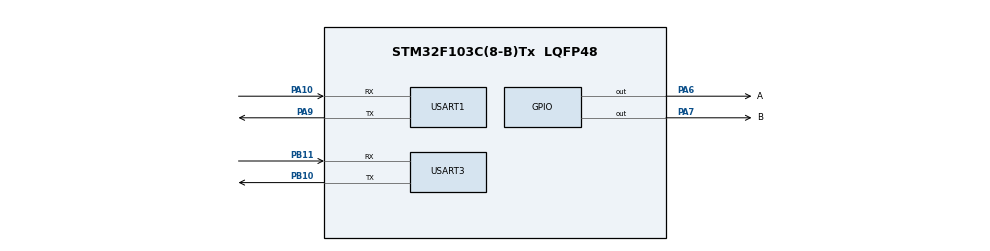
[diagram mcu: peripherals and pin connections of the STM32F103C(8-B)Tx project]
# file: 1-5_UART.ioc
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Mcu.Family=STM32F1
Mcu.Name=STM32F103C(8-B)Tx
Mcu.Package=LQFP48
NVIC.PriorityGroup=NVIC_PRIORITYGROUP_4
PA10.Mode=Asynchronous
PA10.Signal=USART1_RX
PA13.Mode=Serial_Wire
PA13.Signal=SYS_JTMS-SWDIO
PA14.Mode=Serial_Wire
PA14.Signal=SYS_JTCK-SWCLK
PA6.GPIO_Label=A
PA6.Signal=GPIO_Output
PA7.GPIO_Label=B
PA7.Signal=GPIO_Output
PA9.Mode=Asynchronous
PA9.Signal=USART1_TX
PB10.Mode=Asynchronous
PB10.Signal=USART3_TX
PB11.Mode=Asynchronous
PB11.Signal=USART3_RX
ProjectManager.HeapSize=0x200
ProjectManager.StackSize=0x400
ProjectManager.TargetToolchain=STM32CubeIDE
RCC.APB1Freq_Value=8000000
RCC.APB2Freq_Value=8000000
USART1.VirtualMode=VM_ASYNC
USART3.VirtualMode=VM_ASYNC
board=custom

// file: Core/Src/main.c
/* USER CODE BEGIN Header */
/**
  ******************************************************************************
  * @file           : main.c
  * @brief          : Main program body
  ******************************************************************************
  * @attention
  *
  * Copyright (c) 2025 STMicroelectronics.
  * All rights reserved.
  *
  * This software is licensed under terms that can be found in the LICENSE file
  * in the root directory of this software component.
  * If no LICENSE file comes with this software, it is provided AS-IS.
  *
  ******************************************************************************
  */
/* USER CODE END Header */
#include "main.h"
#include "usart.h"
#include "gpio.h"

/* USER CODE BEGIN Includes */
#include "string.h"
/* USER CODE END Includes */

void SystemClock_Config(void);

int main(void)
{

  /* MCU Configuration--------------------------------------------------------*/

  /* Reset of all peripherals, Initializes the Flash interface and the Systick. */
  HAL_Init();

  /* Configure the system clock */
  SystemClock_Config();

  /* Initialize all configured peripherals */
  MX_GPIO_Init();
  MX_USART1_UART_Init();
  MX_USART3_UART_Init();
  /* USER CODE BEGIN 2 */

  char receivData[2] = "A";//存放接收内容 , >>>>>>>>>>>>>>>>！！！必须初始化！！！<<<<<<<<<<<<<<<<

  GPIO_PinState state = GPIO_PIN_RESET;//IO口状态
  /* USER CODE END 2 */

  /* Infinite loop */
  /* USER CODE BEGIN WHILE */
  while (1)
  {
	  	  	  	  	  //外设结构体指针	接收内容存放指针      接收长度(uint8_t*)	   超时时间(一直等待)
	  HAL_UART_Receive(&huart3, (uint8_t*)receivData, strlen(receivData), HAL_MAX_DELAY);//轮询接收

	      /*！>>>>>>>>>>>>>>>>>>>>>>>>>>>> !!!注意 !!!<<<<<<<<<<<<<<<<<<<<<<<<<<<<<<！*/
	  /*若使用strlen()来计算接收大小，必须初始化接收数组,否则strlen()可能会返回一个很大的数,导致串口卡死(超时时间有限也没用)*/

	  	  	  	  	  //外设结构体指针	发送内容指针         发送长度(uint8_t*)	    超时时间(10ms)
	  HAL_UART_Transmit(&huart3,  (uint8_t*)receivData,strlen(receivData),    10);

	  if(receivData[1] == '0'){
		  state = GPIO_PIN_RESET;//状态设置为低电平
	  }
	  else if(receivData[1] == '1'){
		  state = GPIO_PIN_SET;//状态设置为高电平
	  }

	  if(receivData[0] == 'A'){
		  HAL_GPIO_WritePin(A_GPIO_Port, A_Pin, state);//将 A端口 设置状态为 state
	  }
	  else if(receivData[0] == 'B'){
		  HAL_GPIO_WritePin(B_GPIO_Port, B_Pin, state);//将 B端口 设置状态为 state
	  }
    /* USER CODE END WHILE */

  }
}

void SystemClock_Config(void)
{
  RCC_OscInitTypeDef RCC_OscInitStruct = {0};
  RCC_ClkInitTypeDef RCC_ClkInitStruct = {0};

  /** Initializes the RCC Oscillators according to the specified parameters
  * in the RCC_OscInitTypeDef structure.
  */
  RCC_OscInitStruct.OscillatorType = RCC_OSCILLATORTYPE_HSI;
  RCC_OscInitStruct.HSIState = RCC_HSI_ON;
  RCC_OscInitStruct.HSICalibrationValue = RCC_HSICALIBRATION_DEFAULT;
  RCC_OscInitStruct.PLL.PLLState = RCC_PLL_NONE;
  if (HAL_RCC_OscConfig(&RCC_OscInitStruct) != HAL_OK)
  {
    Error_Handler();
  }

  /** Initializes the CPU, AHB and APB buses clocks
  */
  RCC_ClkInitStruct.ClockType = RCC_CLOCKTYPE_HCLK|RCC_CLOCKTYPE_SYSCLK
                              |RCC_CLOCKTYPE_PCLK1|RCC_CLOCKTYPE_PCLK2;
  RCC_ClkInitStruct.SYSCLKSource = RCC_SYSCLKSOURCE_HSI;
  RCC_ClkInitStruct.AHBCLKDivider = RCC_SYSCLK_DIV1;
  RCC_ClkInitStruct.APB1CLKDivider = RCC_HCLK_DIV1;
  RCC_ClkInitStruct.APB2CLKDivider = RCC_HCLK_DIV1;

  if (HAL_RCC_ClockConfig(&RCC_ClkInitStruct, FLASH_LATENCY_0) != HAL_OK)
  {
    Error_Handler();
  }
}

void Error_Handler(void)
{
  __disable_irq();
  while (1)
  {
  }
}
